VERSION ""

NS_ :

BS_:

BU_: CLUSTER_17 ECU_01

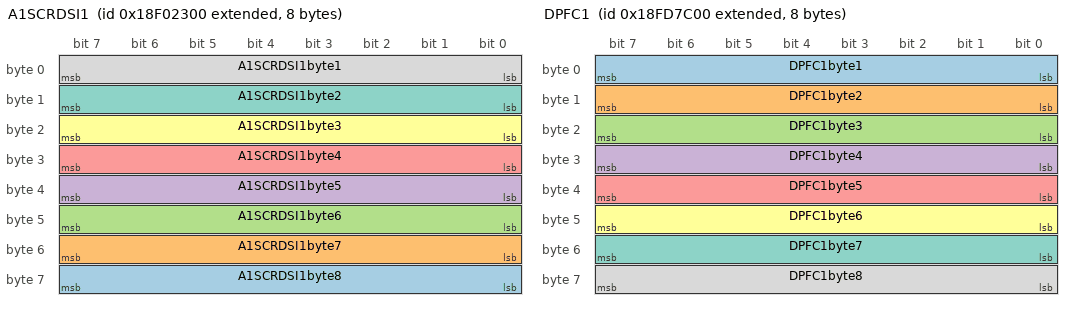
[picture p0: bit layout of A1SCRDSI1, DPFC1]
BO_ 2565874432 A1SCRDSI1: 8 ECU_01
 SG_ A1SCRDSI1byte8 : 56|8@1+ (1,0) [0|255] ""  CLUSTER_17
 SG_ A1SCRDSI1byte7 : 48|8@1+ (1,0) [0|255] ""  CLUSTER_17
 SG_ A1SCRDSI1byte6 : 40|8@1+ (1,0) [0|255] ""  CLUSTER_17
 SG_ A1SCRDSI1byte5 : 32|8@1+ (1,0) [0|255] ""  CLUSTER_17
 SG_ A1SCRDSI1byte4 : 24|8@1+ (1,0) [0|255] ""  CLUSTER_17
 SG_ A1SCRDSI1byte3 : 16|8@1+ (1,0) [0|255] ""  CLUSTER_17
 SG_ A1SCRDSI1byte2 : 8|8@1+ (1,0) [0|255] ""  CLUSTER_17
 SG_ A1SCRDSI1byte1 : 0|8@1+ (1,0) [0|255] ""  CLUSTER_17

BO_ 2566749184 DPFC1: 8 ECU_01
 SG_ DPFC1byte1 : 0|8@1+ (1,0) [0|255] ""  CLUSTER_17
 SG_ DPFC1byte2 : 8|8@1+ (1,0) [0|255] ""  CLUSTER_17
 SG_ DPFC1byte3 : 16|8@1+ (1,0) [0|255] ""  CLUSTER_17
 SG_ DPFC1byte4 : 24|8@1+ (1,0) [0|255] ""  CLUSTER_17
 SG_ DPFC1byte5 : 32|8@1+ (1,0) [0|255] ""  CLUSTER_17
 SG_ DPFC1byte6 : 40|8@1+ (1,0) [0|255] ""  CLUSTER_17
 SG_ DPFC1byte7 : 48|8@1+ (1,0) [0|255] ""  CLUSTER_17
 SG_ DPFC1byte8 : 56|8@1+ (1,0) [0|255] ""  CLUSTER_17

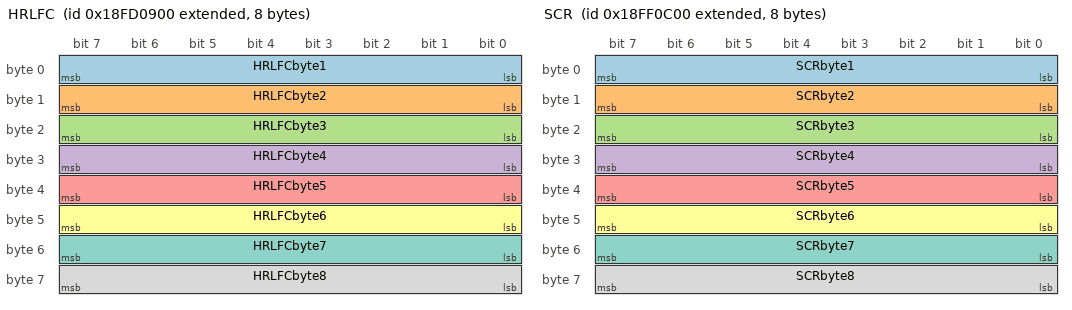
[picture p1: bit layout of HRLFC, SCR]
BO_ 2566719744 HRLFC: 8 ECU_01
 SG_ HRLFCbyte1 : 0|8@1+ (1,0) [0|255] ""  CLUSTER_17
 SG_ HRLFCbyte2 : 8|8@1+ (1,0) [0|255] ""  CLUSTER_17
 SG_ HRLFCbyte3 : 16|8@1+ (1,0) [0|255] ""  CLUSTER_17
 SG_ HRLFCbyte4 : 24|8@1+ (1,0) [0|255] ""  CLUSTER_17
 SG_ HRLFCbyte5 : 32|8@1+ (1,0) [0|255] ""  CLUSTER_17
 SG_ HRLFCbyte6 : 40|8@1+ (1,0) [0|255] ""  CLUSTER_17
 SG_ HRLFCbyte7 : 48|8@1+ (1,0) [0|255] ""  CLUSTER_17
 SG_ HRLFCbyte8 : 56|8@1+ (1,0) [0|255] ""  CLUSTER_17

BO_ 2566851584 SCR: 8 ECU_01
 SG_ SCRbyte1 : 0|8@1+ (1,0) [0|255] ""  CLUSTER_17
 SG_ SCRbyte2 : 8|8@1+ (1,0) [0|255] ""  CLUSTER_17
 SG_ SCRbyte3 : 16|8@1+ (1,0) [0|255] ""  CLUSTER_17
 SG_ SCRbyte4 : 24|8@1+ (1,0) [0|255] ""  CLUSTER_17
 SG_ SCRbyte5 : 32|8@1+ (1,0) [0|255] ""  CLUSTER_17
 SG_ SCRbyte6 : 40|8@1+ (1,0) [0|255] ""  CLUSTER_17
 SG_ SCRbyte7 : 48|8@1+ (1,0) [0|255] ""  CLUSTER_17
 SG_ SCRbyte8 : 56|8@1+ (1,0) [0|255] ""  CLUSTER_17

BA_DEF_ BU_  "ILUsed" ENUM  "No","Yes";
BA_DEF_  "NmBaseAddress" HEX 1024 1087;
BA_DEF_ SG_  "SigType" ENUM  "Default","Range","RangeSigned","ASCII","Discrete","Control","ReferencePGN","DTC","StringDelimiter","StringLength","StringLengthControl","MessageCounter","MessageChecksum";
BA_DEF_ SG_  "GenSigEVName" STRING ;
BA_DEF_ SG_  "GenSigILSupport" ENUM  "No","Yes";
BA_DEF_ SG_  "GenSigSendType" ENUM  "Cyclic","OnWrite","OnWriteWithRepetition","OnChange","OnChangeWithRepetition","IfActive","IfActiveWithRepetition","NoSigSendType";
BA_DEF_ BO_  "GenMsgCycleTimeFast" INT 0 3600000;
BA_DEF_ BO_  "GenMsgILSupport" ENUM  "No","Yes";
BA_DEF_ BU_  "NodeLayerModules" STRING ;
BA_DEF_ BU_  "NmStationAddress" INT 0 255;
BA_DEF_ BO_  "GenMsgSendType" ENUM  "cyclic","NotUsed","IfActive","NotUsed","NotUsed","NotUsed","NotUsed","NotUsed","noMsgSendType";
BA_DEF_ BO_  "GenMsgRequestable" INT 0 1;
BA_DEF_ BO_  "GenMsgCycleTime" INT 0 3600000;
BA_DEF_  "DBName" STRING ;
BA_DEF_  "BusType" STRING ;
BA_DEF_  "ProtocolType" STRING ;
BA_DEF_ BO_  "VFrameFormat" ENUM  "StandardCAN","ExtendedCAN","reserved","J1939PG";
BA_DEF_DEF_  "ILUsed" "Yes";
BA_DEF_DEF_  "NmBaseAddress" 1024;
BA_DEF_DEF_  "SigType" "Default";
BA_DEF_DEF_  "GenSigEVName" "Env@Nodename_@Signame";
BA_DEF_DEF_  "GenSigILSupport" "Yes";
BA_DEF_DEF_  "GenSigSendType" "NoSigSendType";
BA_DEF_DEF_  "GenMsgCycleTimeFast" 0;
BA_DEF_DEF_  "GenMsgILSupport" "Yes";
BA_DEF_DEF_  "NodeLayerModules" "CANoeILNLVector.dll";
BA_DEF_DEF_  "NmStationAddress" 254;
BA_DEF_DEF_  "GenMsgSendType" "noMsgSendType";
BA_DEF_DEF_  "GenMsgRequestable" 1;
BA_DEF_DEF_  "GenMsgCycleTime" 0;
BA_DEF_DEF_  "DBName" "";
BA_DEF_DEF_  "BusType" "CAN";
BA_DEF_DEF_  "ProtocolType" "J1939";
BA_DEF_DEF_  "VFrameFormat" "J1939PG";
BA_ "ProtocolType" "";
BA_ "DBName" "CAN1";
BA_ "NmStationAddress" BU_ CLUSTER_17 23;
BA_ "NmStationAddress" BU_ ECU_01 0;
BA_ "VFrameFormat" BO_ 2565874432 1;
BA_ "GenMsgCycleTimeFast" BO_ 2565874432 50;
BA_ "GenMsgCycleTime" BO_ 2565874432 50;
BA_ "GenMsgSendType" BO_ 2565874432 0;
BA_ "GenMsgCycleTimeFast" BO_ 2566749184 1000;
BA_ "GenMsgSendType" BO_ 2566749184 0;
BA_ "GenMsgCycleTime" BO_ 2566749184 1000;
BA_ "VFrameFormat" BO_ 2566749184 1;
BA_ "GenMsgCycleTimeFast" BO_ 2566719744 1000;
BA_ "GenMsgSendType" BO_ 2566719744 0;
BA_ "GenMsgCycleTime" BO_ 2566719744 1000;
BA_ "VFrameFormat" BO_ 2566719744 1;
BA_ "GenMsgCycleTimeFast" BO_ 2566851584 1000;
BA_ "GenMsgSendType" BO_ 2566851584 0;
BA_ "GenMsgCycleTime" BO_ 2566851584 1000;
BA_ "VFrameFormat" BO_ 2566851584 1;
